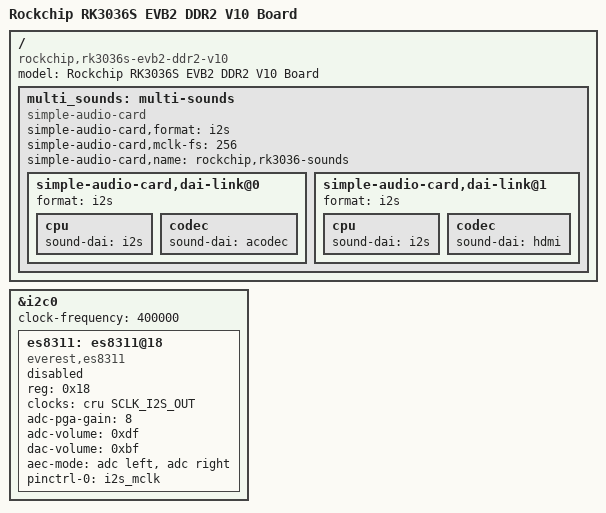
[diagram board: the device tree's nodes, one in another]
// SPDX-License-Identifier: (GPL-2.0+ OR MIT)
/*
 * Copyright (c) 2024 Rockchip Electronics Co., Ltd
 *
 */

/dts-v1/;

#include "rk3036s-evb1-ddr3-v10.dts"
#include <dt-bindings/input/input.h>

/ {
	model = "Rockchip RK3036S EVB2 DDR2 V10 Board";
	compatible = "rockchip,rk3036s-evb2-ddr2-v10", "rockchip,rk3036";

	/delete-node/ multi-sounds;
	multi_sounds: multi-sounds {
		status = "okay";
		compatible = "simple-audio-card";
		simple-audio-card,format = "i2s";
		simple-audio-card,mclk-fs = <256>;
		simple-audio-card,name = "rockchip,rk3036-sounds";
		simple-audio-card,dai-link@0 {
			format = "i2s";
			cpu {
				sound-dai = <&i2s>;
			};
			codec {
				sound-dai = <&acodec>;
			};
		};
		simple-audio-card,dai-link@1 {
			format = "i2s";
			cpu {
				sound-dai = <&i2s>;
			};
			codec {
				sound-dai = <&hdmi>;
			};
		};
		/*simple-audio-card,dai-link@2 {
			format = "i2s";
			cpu {
				sound-dai = <&i2s>;
			};
			codec {
				sound-dai = <&es8311>;
			};
		};
		*/
	};
};

&i2c0 {
	clock-frequency = <400000>;
	status = "okay";

	es8311: es8311@18 {
		status = "disabled";
		compatible = "everest,es8311";
		reg = <0x18>;
		clocks = <&cru SCLK_I2S_OUT>;
		clock-names = "mclk";
		adc-pga-gain = <8>;
		adc-volume = <0xdf>;
		dac-volume = <0xbf>;
		aec-mode = "adc left, adc right";
		pinctrl-names = "default";
		pinctrl-0 = <&i2s_mclk>;

		/*
		 * in rk3036-evb-v10,es8311 is not actually connected
		 * to PA,so we don't need spk-ctl-gpios
		 */
		/*spk-ctl-gpios = ;*/

		#sound-dai-cells = <0>;
	};
};
